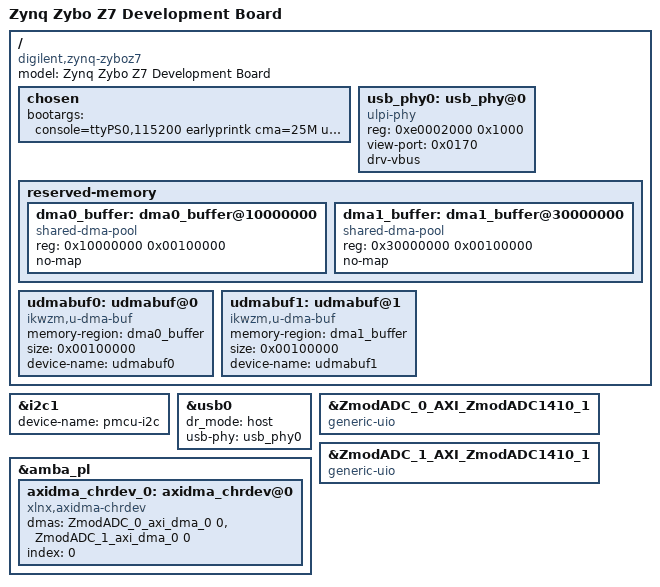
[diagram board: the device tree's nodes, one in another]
/include/ "system-conf.dtsi"
/ {
	model = "Zynq Zybo Z7 Development Board";
	compatible = "digilent,zynq-zyboz7", "xlnx,zynq-7000";

	chosen {
		bootargs = "console=ttyPS0,115200 earlyprintk cma=25M uio_pdrv_genirq.of_id=generic-uio root=/dev/mmcblk0p2 rw rootwait";
	};

	usb_phy0: usb_phy@0 {
		compatible = "ulpi-phy";
		#phy-cells = <0>;
		reg = <0xe0002000 0x1000>;
		view-port = <0x0170>;
		drv-vbus;
	};
    reserved-memory {
        #address-cells = <1>;
        #size-cells = <1>;
        ranges;

        dma0_buffer: dma0_buffer@10000000 {
            reg = <0x10000000 0x00100000>; // 1 MB at 256 MB
            no-map;
            compatible = "shared-dma-pool";
        };

        dma1_buffer: dma1_buffer@30000000 {
            reg = <0x30000000 0x00100000>; // 1 MB at 768 MB
            no-map;
            compatible = "shared-dma-pool";
        };
    };

    udmabuf0: udmabuf@0 {
        compatible = "ikwzm,u-dma-buf";
        memory-region = <&dma0_buffer>;
        size = <0x00100000>;
        device-name = "udmabuf0";
    };

    udmabuf1: udmabuf@1 {
        compatible = "ikwzm,u-dma-buf";
        memory-region = <&dma1_buffer>;
        size = <0x00100000>;
        device-name = "udmabuf1";
    };

};

&i2c1 {
        status = "okay";
        device-name = "pmcu-i2c";
};

&usb0 {
	dr_mode = "host";
	status 	= "okay";
	usb-phy = <&usb_phy0>;
};

&ZmodADC_0_AXI_ZmodADC1410_1 {
    compatible = "generic-uio";
};

&ZmodADC_1_AXI_ZmodADC1410_1 {
    compatible = "generic-uio";
};

&amba_pl {
    axidma_chrdev_0: axidma_chrdev@0 {
        compatible = "xlnx,axidma-chrdev";
        dmas = <&ZmodADC_0_axi_dma_0 0>, <&ZmodADC_1_axi_dma_0 0>;
        dma-names = "rx_channel_0", "rx_channel_1";
        index = <0>;
    };
};
